# RZT2L register map
Vendor: Renesas Electronics Corporation; Series: RZT; File version: 1.20.00
CPU: other r0p0, little endian, MPU, no FPU, VTOR, 4 interrupt priority bits, 624 interrupts
Registers are 32-bit, read-write, reset 0x0 unless marked. A register's access mark holds for its fields unless they carry their own. Offsets are from the block's base; [hi:lo] are bit positions; {n}, {i} and the like mark numbered series; 'fields as' and 'values as' point back to an identical list.

## SYSC_NS — System Control for Non-safety region
Base 0x80280000
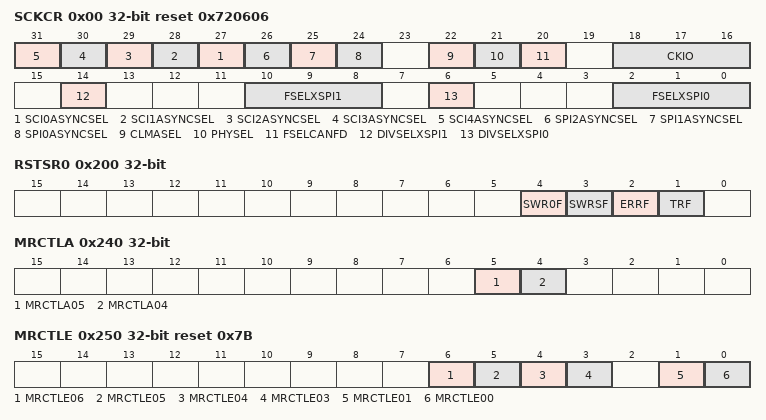
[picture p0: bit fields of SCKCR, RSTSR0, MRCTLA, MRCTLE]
0x00 SCKCR reset 0x720606 — System Clock Control Register
  [n+27] SCI{n}ASYNCSEL (n=0..4) — Select clock frequency when asynchronous serial clock is selected in SCI{n}
    0=75.0 MHz; 1=96.0 MHz
  [26] SPI2ASYNCSEL — Select clock frequency when asynchronous serial clock is selected in SPI2
    0=75.0 MHz; 1=96.0 MHz
  [25] SPI1ASYNCSEL — Select clock frequency when asynchronous serial clock is selected in SPI1
    0=75.0 MHz; 1=96.0 MHz
  [24] SPI0ASYNCSEL — Select clock frequency when asynchronous serial clock is selected in SPI0
    0=75.0 MHz; 1=96.0 MHz
  [22] CLMASEL — Select alternative clock when main clock abnormal oscillation is detected in CLMA3
    0=LOCO; 1=PLL
  [21] PHYSEL — Select the Ethernet PHY reference clock output (ETHn_REFCLK, n = 0 to 2)
    0=PLL1 divider clock; 1=Main clock oscillator
  [20] FSELCANFD — Select the frequency of the clock supplied to CANFD
    0=80.0 MHz; 1=40.0 MHz
  [18:16] CKIO — Set the frequency of the external bus clock (CKIO) and the clock supplied to BSC in combination with the DIVSELSUB in the SCKCR2 register. The combination is shown below.
  [14] DIVSELXSPI1 — Select the base clock to generate serial clock for xSPI Unit 1
    0=800 MHz; 1=600 MHz
  [10:8] FSELXSPI1 — Set the frequency of the clock provided to xSPI Unit 1 in combination with bit 14 (DIVSELXSPI1).
  [6] DIVSELXSPI0 — Select the base clock to generate serial clock for xSPI Unit 0
    0=800 MHz; 1=600 MHz
  [2:0] FSELXSPI0 — Set the frequency of the clock provided to xSPI Unit 0 in combination with bit 6 (DIVSELXSPI0). The combination is shown below.
0x200 RSTSR0 (reset mask 0xFFFFFFE1) — Reset Status Register 0
  [4] SWR0F — CPU0 Software Reset Detect Flag
    0=CPU0 software reset not detected; 1=CPU0 software reset detected
  [3] SWRSF — System Software Reset Detect Flag
    0=System software reset not detected; 1=System software reset detected
  [2] ERRF — Error Reset Detect Flag
    0=Error reset not detected; 1=Error reset detected
  [1] TRF — RES# Pin Reset Detect Flag
    0=RES# pin reset not detected; 1=RES# pin reset detected
0x240 MRCTLA — Module Reset Control Register A
  [5] MRCTLA05 — xSPI Unit 1 Reset Control
    0=xSPI Unit 1 is released from reset; 1=xSPI Unit 1 is in the reset state
  [4] MRCTLA04 — xSPI Unit 0 Reset Control
    0=xSPI Unit 0 is released from reset; 1=xSPI Unit 0 is in the reset state
0x250 MRCTLE reset 0x7B — Module Reset Control Register E
  [6] MRCTLE06 — MII Converter Reset Control
    0=MII converter is released from reset; 1=MII converter is in the reset state
  [5] MRCTLE05 — Ethernet Subsystem Register Reset Control
    0=Ethernet Subsystem register is released from reset; 1=Ethernet Subsystem register is in the reset state
  [4] MRCTLE04 — ESC (IP clock domain) Reset Control
    0=ESC (IP clock domain) is released from reset; 1=ESC (IP clock domain) is in the reset state
  [3] MRCTLE03 — ESC (Bus clock domain) Reset Control
    0=ESC (Bus clock domain) is released from reset; 1=ESC (Bus clock domain) is in the reset state
  [1] MRCTLE01 — GMAC (PCLKM clock domain) Reset Control
    0=GMAC (PCLKM clock domain) is released from reset; 1=GMAC (PCLKM clock domain) is in the reset state
  [0] MRCTLE00 — GMAC (PCLKH clock domain) Reset Control
    0=GMAC (PCLKH clock domain) is released from reset; 1=GMAC (PCLKH clock domain) is in the reset state
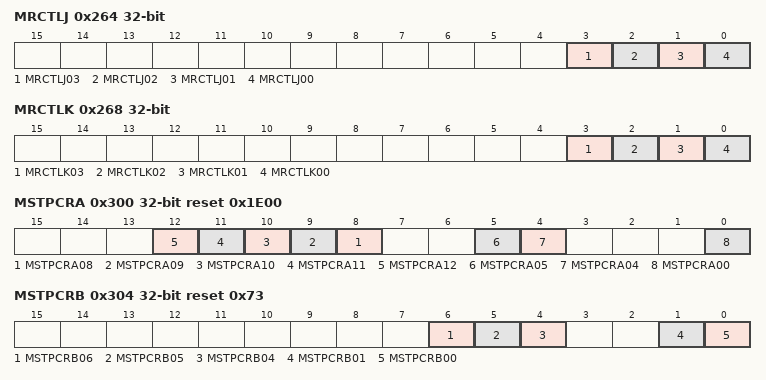
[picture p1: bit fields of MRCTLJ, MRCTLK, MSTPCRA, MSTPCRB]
0x264 MRCTLJ — Module Reset Control Register J
  [3] MRCTLJ03 — ENDAT0 Reset Control
    0=ENDAT0 is released from reset; 1=ENDAT0 is in the reset state
  [2] MRCTLJ02 — BISS0 Reset Control
    0=BISS0 is released from reset; 1=BISS0 is in the reset state
  [1] MRCTLJ01 — HDSL0 Reset Control
    0=HDSL0 is released from reset; 1=HDSL0 is in the reset state
  [0] MRCTLJ00 — AFMT0 Reset Control
    0=AFMT0 is released from reset; 1=AFMT0 is in the reset state
0x268 MRCTLK — Module Reset Control Register K
  [3] MRCTLK03 — ENDAT1 Reset Control
    0=ENDAT1 is released from reset; 1=ENDAT1 is in the reset state
  [2] MRCTLK02 — BISS1 Reset Control
    0=BISS1 is released from reset; 1=BISS1 is in the reset state
  [1] MRCTLK01 — HDSL1 Reset Control
    0=HDSL1 is released from reset; 1=HDSL1 is in the reset state
  [0] MRCTLK00 — AFMT1 Reset Control
    0=AFMT1 is released from reset; 1=AFMT1 is in the reset state
0x300 MSTPCRA reset 0x1E00 (reset mask 0xFFFFFECE) — Module Stop Control Register A
  [all] fields
    0=Release from the module-stop state; 1=Transition to the module-stop state is made
  [n] MSTPCRA{n:02} (n=8..12) — SCI Unit {n-8} Module Stop
  [5] MSTPCRA05 — xSPI Unit 1 Module Stop
  [4] MSTPCRA04 — xSPI Unit 0 Module Stop
  [0] MSTPCRA00 — BSC Module Stop
0x304 MSTPCRB reset 0x73 — Module Stop Control Register B
  [all] fields
    values as the fields of MSTPCRA
  [6] MSTPCRB06 — SPI Unit 2 Module Stop
  [5] MSTPCRB05 — SPI Unit 1 Module Stop
  [4] MSTPCRB04 — SPI Unit 0 Module Stop
  [1] MSTPCRB01 — IIC Unit 1 Module Stop
  [0] MSTPCRB00 — IIC Unit 0 Module Stop
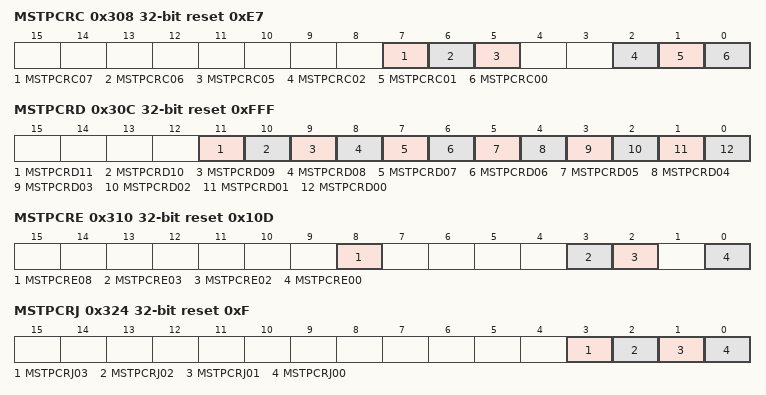
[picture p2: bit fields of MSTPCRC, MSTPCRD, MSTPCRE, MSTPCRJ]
0x308 MSTPCRC reset 0xE7 — Module Stop Control Register C
  [all] fields
    values as the fields of MSTPCRA
  [7] MSTPCRC07 — ADC12 Unit 1 Module Stop
  [6] MSTPCRC06 — ADC12 Unit 0 Module Stop
  [5] MSTPCRC05 — TFU Module Stop
  [2] MSTPCRC02 — GPT Unit 1 Module Stop
  [1] MSTPCRC01 — GPT Unit 0 Module Stop
  [0] MSTPCRC00 — MTU3 Module Stop
0x30C MSTPCRD reset 0xFFF — Module Stop Control Register D
  [11] MSTPCRD11 — CKIO Module Stop
    values as the fields of MSTPCRA
  [10] MSTPCRD10 — CANFD Module Stop
    0=Release from the module-stop state; 1=Transition to the module stop state is made
  [9] MSTPCRD09 — CRC Unit 0 Module Stop
    values as the fields of MSTPCRA
  [8] MSTPCRD08 — DOC Module Stop
    values as the fields of MSTPCRA
  [7] MSTPCRD07 — TSU Module Stop
    values as MSTPCRD10
  [6] MSTPCRD06 — CMTW Unit 1 Module Stop
    values as the fields of MSTPCRA
  [5] MSTPCRD05 — CMTW Unit 0 Module Stop
    values as the fields of MSTPCRA
  [4] MSTPCRD04 — CMT Unit 2 Module Stop
    values as the fields of MSTPCRA
  [3] MSTPCRD03 — CMT Unit 1 Module Stop
    values as the fields of MSTPCRA
  [2] MSTPCRD02 — CMT Unit 0 Module Stop
    values as the fields of MSTPCRA
  [1] MSTPCRD01 — DSMIF Unit 1 Module Stop
    values as the fields of MSTPCRA
  [0] MSTPCRD00 — DSMIF Unit 0 Module Stop
    values as the fields of MSTPCRA
0x310 MSTPCRE reset 0x10D — Module Stop Control Register E
  [all] fields
    values as the fields of MSTPCRA
  [8] MSTPCRE08 — USB Module Stop
  [3] MSTPCRE03 — Ethernet Subsystem Register Module Stop
  [2] MSTPCRE02 — ESC Module Stop
  [0] MSTPCRE00 — GMAC Module Stop
0x324 MSTPCRJ reset 0xF — Module Stop Control Register J
  [all] fields
    values as the fields of MSTPCRA
  [3] MSTPCRJ03 — ENDAT0 Module Stop
  [2] MSTPCRJ02 — BISS0 Module Stop
  [1] MSTPCRJ01 — HDSL0 Module Stop
  [0] MSTPCRJ00 — AFMT0 Module Stop
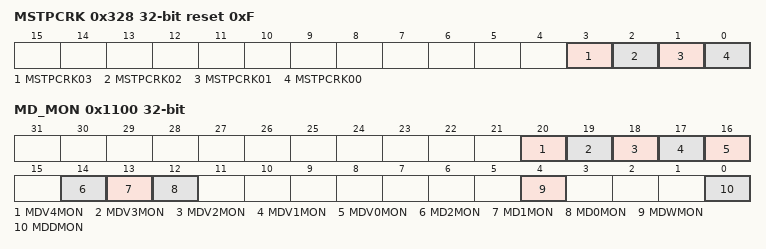
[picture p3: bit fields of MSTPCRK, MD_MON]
0x328 MSTPCRK reset 0xF — Module Stop Control Register K
  [all] fields
    values as the fields of MSTPCRA
  [3] MSTPCRK03 — ENDAT1 Module Stop
  [2] MSTPCRK02 — BISS1 Module Stop
  [1] MSTPCRK01 — HDSL1 Module Stop
  [0] MSTPCRK00 — AFMT1 Module Stop
0x32C MSTPCRL reset 0x1 — Module Stop Control Register L
  [0] MSTPCRL00 — ENCOUT Module Stop
    values as the fields of MSTPCRA
0x1100 MD_MON ro (reset mask 0xFFE08FEE) — Operating Mode Monitor Register
  [20] MDV4MON — MDV4 status flag (xSPI1 domain)
  [19] MDV3MON — MDV3 status flag (xSPI0 domain)
  [18] MDV2MON — MDV2 status flag (ETH2 domain)
  [17] MDV1MON — MDV1 status flag (ETH1 domain)
  [16] MDV0MON — MDV0 status flag (ETH0 domain)
  [14] MD2MON — MD2 pin status flag
  [13] MD1MON — MD1 pin status flag
  [12] MD0MON — MD0 pin status flag
  [4] MDWMON — MDW status flag
  [0] MDDMON — MDD status flag
